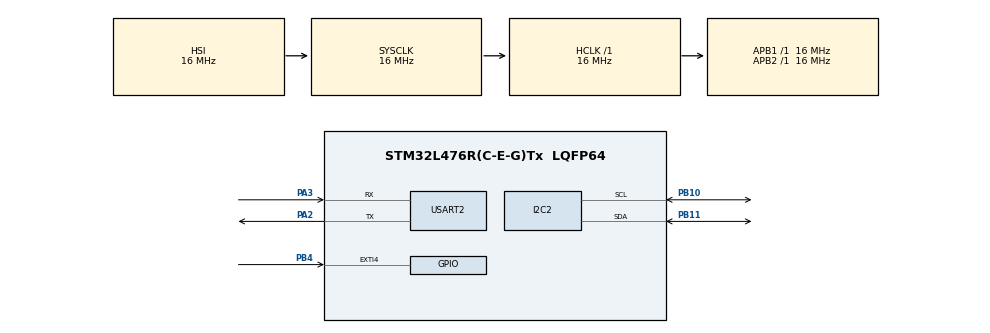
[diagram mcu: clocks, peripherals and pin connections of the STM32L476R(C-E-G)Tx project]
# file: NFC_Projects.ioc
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I2C2.Timing=0x00303D5B
Mcu.Family=STM32L4
Mcu.Name=STM32L476R(C-E-G)Tx
Mcu.Package=LQFP64
NVIC.EXTI4_IRQn=true\:0\:0\:false\:false\:true\:true\:true
NVIC.I2C2_ER_IRQn=true\:0\:0\:false\:false\:true\:true\:true
NVIC.I2C2_EV_IRQn=true\:0\:0\:false\:false\:true\:true\:true
NVIC.PriorityGroup=NVIC_PRIORITYGROUP_4
PA13\ (JTMS-SWDIO).Mode=Serial_Wire
PA13\ (JTMS-SWDIO).Signal=SYS_JTMS-SWDIO
PA14\ (JTCK-SWCLK).Mode=Serial_Wire
PA14\ (JTCK-SWCLK).Signal=SYS_JTCK-SWCLK
PA2.Mode=Asynchronous
PA2.Signal=USART2_TX
PA3.Mode=Asynchronous
PA3.Signal=USART2_RX
PB10.Mode=I2C
PB10.Signal=I2C2_SCL
PB11.Mode=I2C
PB11.Signal=I2C2_SDA
PB4\ (NJTRST).GPIO_ModeDefaultEXTI=GPIO_MODE_IT_FALLING
PB4\ (NJTRST).Signal=GPXTI4
ProjectManager.HeapSize=0x200
ProjectManager.StackSize=0x400
ProjectManager.TargetToolchain=STM32CubeIDE
RCC.ADCFreq_Value=64000000
RCC.AHBFreq_Value=16000000
RCC.APB1Freq_Value=16000000
RCC.APB1TimFreq_Value=16000000
RCC.APB2Freq_Value=16000000
RCC.APB2TimFreq_Value=16000000
RCC.CortexFreq_Value=16000000
RCC.HCLKFreq_Value=16000000
RCC.HSE_VALUE=8000000
RCC.HSI_VALUE=16000000
RCC.LSE_VALUE=32768
RCC.MSI_VALUE=4000000
RCC.PLLSourceVirtual=RCC_PLLSOURCE_HSI
RCC.SYSCLKFreq_VALUE=16000000
RCC.SYSCLKSource=RCC_SYSCLKSOURCE_HSI
RCC.USBFreq_Value=64000000
RCC.VCOOutputFreq_Value=128000000
USART2.VirtualMode-Asynchronous=VM_ASYNC
board=custom

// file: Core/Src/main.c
/* USER CODE BEGIN Header */
/**
  ******************************************************************************
  * @file           : main.c
  * @brief          : Main program body
  ******************************************************************************
  * @attention
  *
  * <h2><center>&copy; Copyright (c) 2020 STMicroelectronics.
  * All rights reserved.</center></h2>
  *
  * This software component is licensed by ST under BSD 3-Clause license,
  * the "License"; You may not use this file except in compliance with the
  * License. You may obtain a copy of the License at:
  *                        opensource.org/licenses/BSD-3-Clause
  *
  ******************************************************************************
  */
/* USER CODE END Header */
#include "main.h"

I2C_HandleTypeDef hi2c2;

UART_HandleTypeDef huart2;

void SystemClock_Config(void);
static void MX_GPIO_Init(void);
static void MX_I2C2_Init(void);
static void MX_USART2_UART_Init(void);

/* USER CODE BEGIN 0 */

/**This function is used to configure a protected memory
 *
 * The user memory is between 0x04 and 0xE1
 *
 * So it may you will want to less some area for unprotected
 *
 * start address is between 0x04 and 0xE1
 * */

/**This function callback when an NFC device is present
 *
 * */
void HAL_GPIO_EXTI_Callback(uint16_t GPIO_Pin){

	/* We loop until we RF field switch off*/

	while(HAL_GPIO_ReadPin(GPIOB, GPIO_PIN_4));

	/* Please put here your code, if you want to read something from NFC or write something to NFC*/

}
/* USER CODE END 0 */

int main(void)
{
  /* USER CODE BEGIN 1 */
	uint8_t data[20]={};
	uint8_t buffer[20]={};
  /* USER CODE END 1 */

  /* MCU Configuration--------------------------------------------------------*/

  /* Reset of all peripherals, Initializes the Flash interface and the Systick. */
  HAL_Init();

  /* Configure the system clock */
  SystemClock_Config();

  /* Initialize all configured peripherals */
  MX_GPIO_Init();
  MX_I2C2_Init();
  MX_USART2_UART_Init();
  /* USER CODE BEGIN 2 */

  read_From_NFC(1,data,nfc_address_recommended);

  /* USER CODE END 2 */

  /* Infinite loop */
  while (1)
  {

  }
}

void SystemClock_Config(void)
{
  RCC_OscInitTypeDef RCC_OscInitStruct = {0};
  RCC_ClkInitTypeDef RCC_ClkInitStruct = {0};
  RCC_PeriphCLKInitTypeDef PeriphClkInit = {0};

  /** Initializes the RCC Oscillators according to the specified parameters
  * in the RCC_OscInitTypeDef structure.
  */
  RCC_OscInitStruct.OscillatorType = RCC_OSCILLATORTYPE_HSI;
  RCC_OscInitStruct.HSIState = RCC_HSI_ON;
  RCC_OscInitStruct.HSICalibrationValue = RCC_HSICALIBRATION_DEFAULT;
  RCC_OscInitStruct.PLL.PLLState = RCC_PLL_NONE;
  if (HAL_RCC_OscConfig(&RCC_OscInitStruct) != HAL_OK)
  {
    Error_Handler();
  }
  /** Initializes the CPU, AHB and APB buses clocks
  */
  RCC_ClkInitStruct.ClockType = RCC_CLOCKTYPE_HCLK|RCC_CLOCKTYPE_SYSCLK
                              |RCC_CLOCKTYPE_PCLK1|RCC_CLOCKTYPE_PCLK2;
  RCC_ClkInitStruct.SYSCLKSource = RCC_SYSCLKSOURCE_HSI;
  RCC_ClkInitStruct.AHBCLKDivider = RCC_SYSCLK_DIV1;
  RCC_ClkInitStruct.APB1CLKDivider = RCC_HCLK_DIV1;
  RCC_ClkInitStruct.APB2CLKDivider = RCC_HCLK_DIV1;

  if (HAL_RCC_ClockConfig(&RCC_ClkInitStruct, FLASH_LATENCY_0) != HAL_OK)
  {
    Error_Handler();
  }
  PeriphClkInit.PeriphClockSelection = RCC_PERIPHCLK_USART2|RCC_PERIPHCLK_I2C2;
  PeriphClkInit.Usart2ClockSelection = RCC_USART2CLKSOURCE_PCLK1;
  PeriphClkInit.I2c2ClockSelection = RCC_I2C2CLKSOURCE_PCLK1;
  if (HAL_RCCEx_PeriphCLKConfig(&PeriphClkInit) != HAL_OK)
  {
    Error_Handler();
  }
  /** Configure the main internal regulator output voltage
  */
  if (HAL_PWREx_ControlVoltageScaling(PWR_REGULATOR_VOLTAGE_SCALE1) != HAL_OK)
  {
    Error_Handler();
  }
}

static void MX_I2C2_Init(void)
{

  hi2c2.Instance = I2C2;
  hi2c2.Init.Timing = 0x00303D5B;
  hi2c2.Init.OwnAddress1 = 0;
  hi2c2.Init.AddressingMode = I2C_ADDRESSINGMODE_7BIT;
  hi2c2.Init.DualAddressMode = I2C_DUALADDRESS_DISABLE;
  hi2c2.Init.OwnAddress2 = 0;
  hi2c2.Init.OwnAddress2Masks = I2C_OA2_NOMASK;
  hi2c2.Init.GeneralCallMode = I2C_GENERALCALL_DISABLE;
  hi2c2.Init.NoStretchMode = I2C_NOSTRETCH_DISABLE;
  if (HAL_I2C_Init(&hi2c2) != HAL_OK)
  {
    Error_Handler();
  }
  /** Configure Analogue filter
  */
  if (HAL_I2CEx_ConfigAnalogFilter(&hi2c2, I2C_ANALOGFILTER_ENABLE) != HAL_OK)
  {
    Error_Handler();
  }
  /** Configure Digital filter
  */
  if (HAL_I2CEx_ConfigDigitalFilter(&hi2c2, 0) != HAL_OK)
  {
    Error_Handler();
  }

}

static void MX_USART2_UART_Init(void)
{

  huart2.Instance = USART2;
  huart2.Init.BaudRate = 115200;
  huart2.Init.WordLength = UART_WORDLENGTH_8B;
  huart2.Init.StopBits = UART_STOPBITS_1;
  huart2.Init.Parity = UART_PARITY_NONE;
  huart2.Init.Mode = UART_MODE_TX_RX;
  huart2.Init.HwFlowCtl = UART_HWCONTROL_NONE;
  huart2.Init.OverSampling = UART_OVERSAMPLING_16;
  huart2.Init.OneBitSampling = UART_ONE_BIT_SAMPLE_DISABLE;
  huart2.AdvancedInit.AdvFeatureInit = UART_ADVFEATURE_NO_INIT;
  if (HAL_UART_Init(&huart2) != HAL_OK)
  {
    Error_Handler();
  }

}

static void MX_GPIO_Init(void)
{
  GPIO_InitTypeDef GPIO_InitStruct = {0};

  /* GPIO Ports Clock Enable */
  __HAL_RCC_GPIOA_CLK_ENABLE();
  __HAL_RCC_GPIOB_CLK_ENABLE();

  /*Configure GPIO pin : PB4 */
  GPIO_InitStruct.Pin = GPIO_PIN_4;
  GPIO_InitStruct.Mode = GPIO_MODE_IT_FALLING;
  GPIO_InitStruct.Pull = GPIO_NOPULL;
  HAL_GPIO_Init(GPIOB, &GPIO_InitStruct);

  /* EXTI interrupt init*/
  HAL_NVIC_SetPriority(EXTI4_IRQn, 0, 0);
  HAL_NVIC_EnableIRQ(EXTI4_IRQn);

}

/* USER CODE BEGIN 4 */
/**
 * @brief CRC_A
 *
 */

/* USER CODE END 4 */

void Error_Handler(void)
{
  __disable_irq();
  while (1)
  {
  }
}

/************************ (C) COPYRIGHT STMicroelectronics *****END OF FILE****/
